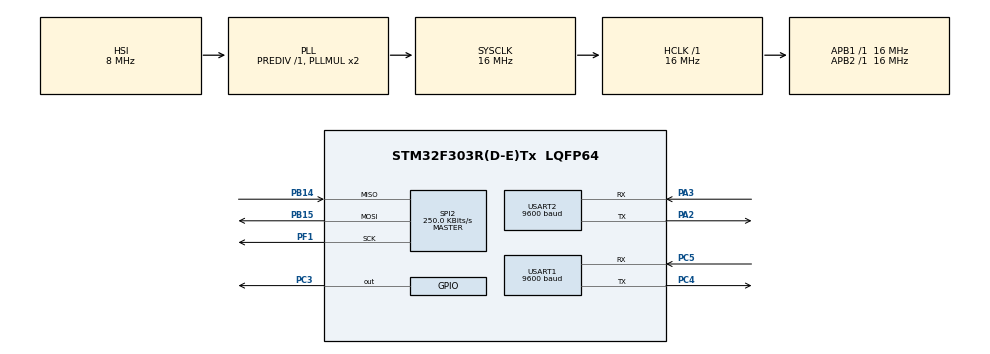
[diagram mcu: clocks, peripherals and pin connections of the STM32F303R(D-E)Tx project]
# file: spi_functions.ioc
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Mcu.Family=STM32F3
Mcu.Name=STM32F303R(D-E)Tx
Mcu.Package=LQFP64
NVIC.PriorityGroup=NVIC_PRIORITYGROUP_4
PA2.Mode=Asynchronous
PA2.Signal=USART2_TX
PA3.Mode=Asynchronous
PA3.Signal=USART2_RX
PB14.Mode=Full_Duplex_Master
PB14.Signal=SPI2_MISO
PB15.Mode=Full_Duplex_Master
PB15.Signal=SPI2_MOSI
PC3.Signal=GPIO_Output
PC4.Mode=Asynchronous
PC4.Signal=USART1_TX
PC5.Mode=Asynchronous
PC5.Signal=USART1_RX
PF1-OSC_OUT.Mode=Full_Duplex_Master
PF1-OSC_OUT.Signal=SPI2_SCK
ProjectManager.HeapSize=0x200
ProjectManager.StackSize=0x400
ProjectManager.TargetToolchain=STM32CubeIDE
RCC.AHBFreq_Value=16000000
RCC.APB1Freq_Value=16000000
RCC.APB1TimFreq_Value=16000000
RCC.APB2Freq_Value=16000000
RCC.APB2TimFreq_Value=16000000
RCC.CortexFreq_Value=16000000
RCC.HCLKFreq_Value=16000000
RCC.HSE_VALUE=8000000
RCC.HSI_VALUE=8000000
RCC.LSE_VALUE=32768
RCC.SYSCLKFreq_VALUE=16000000
RCC.SYSCLKSourceVirtual=RCC_SYSCLKSOURCE_PLLCLK
RCC.USBFreq_Value=16000000
SPI2.BaudRatePrescaler=SPI_BAUDRATEPRESCALER_64
SPI2.CalculateBaudRate=250.0 KBits/s
SPI2.DataSize=SPI_DATASIZE_8BIT
SPI2.Direction=SPI_DIRECTION_2LINES
SPI2.Mode=SPI_MODE_MASTER
SPI2.VirtualType=VM_MASTER
USART1.BaudRate=9600
USART1.Mode=MODE_TX_RX
USART1.OverrunDisableParam=ADVFEATURE_OVERRUN_DISABLE
USART1.VirtualMode-Asynchronous=VM_ASYNC
USART2.BaudRate=9600
USART2.VirtualMode-Asynchronous=VM_ASYNC
board=custom

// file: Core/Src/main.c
/* USER CODE BEGIN Header */
/**
 ******************************************************************************
 * @file           : main.c
 * @brief          : Main program body
 ******************************************************************************
 * @attention
 *
 * Copyright (c) 2022 STMicroelectronics.
 * All rights reserved.
 *
 * This software is licensed under terms that can be found in the LICENSE file
 * in the root directory of this software component.
 * If no LICENSE file comes with this software, it is provided AS-IS.
 *
 ******************************************************************************
 */
/* USER CODE END Header */
#include "main.h"
#include "INC_MAX86178.h"

SPI_HandleTypeDef hspi2;

UART_HandleTypeDef huart1;
UART_HandleTypeDef huart2;

void SystemClock_Config(void);
static void MX_GPIO_Init(void);
static void MX_SPI2_Init(void);
static void MX_USART2_UART_Init(void);
static void MX_USART1_UART_Init(void);

int main(void)
{

  /* MCU Configuration--------------------------------------------------------*/

  /* Reset of all peripherals, Initializes the Flash interface and the Systick. */
  HAL_Init();

  /* Configure the system clock */
  SystemClock_Config();

  /* Initialize all configured peripherals */
  MX_GPIO_Init();
  MX_SPI2_Init();
  MX_USART2_UART_Init();
  MX_USART1_UART_Init();

  /* Infinite loop */
  /* USER CODE BEGIN WHILE */

							////  10011110 10100100 10010100
							//
							////  11110000 00000000 00000000
							//
							//x[2] x[3] x[4]
							//
							// temp=  x[2]>>4
							//
							//base = 0x000000
							//
							//temp2  = 00001111 & x[2]
							//
							//
							//  32 -> x[3]
							//
							//  32 - > x[4]
							//
							//32 - > temp2
							//
							//            temp2    x[3]     x[4]
							//00000000 000000000 00000000 00000000
							//
							//temp3 -> 32 = 000
							//
							//temp2<<16
							//temp3 = temp3 | temp2
							//
							//
							//x[3]<<8
							//temp3 = temp3 | x[3]
							//
							//temp3 = temp3 | x[4]
							//
							//
							//temp3 = -1*temp3 - > value

	///
//	int number=9000;
	unsigned char *x;
//	uint32_t c1=0,c2=0,c3=0,c4=0,c5=0,c6=0,c7=0,c8=0,c9=0;
//	uint32_t sample[number];
//	uint32_t samples_p1_m1[500];
//	uint32_t samples_p2_m1[500];
//	uint32_t samples_p1_m2[500];
//	uint32_t samples_p2_m2[500];
//	uint32_t samples_p1_m3[500];
//	uint32_t samples_p2_m3[500];

//	memset(sample, 0, number*sizeof(sample[0]));

///reading ppg data

	x=ppg_init();

///accumulating samples in a array

//	for (int l =0 ;l<number;l=l+2){
//			sample[l] = *(x+l);
//		}
//
//
/////Segregating samples based on tags
//
//	for(int l=0;l<number;l=l+6){
//
//		temp1 = (uint8_t)sample[l];
//		temp1 = temp1 >> 4;
//
//		switch(temp1){
//
//				case 0x00: // measurement 1 ===> 00
//						{
//							samples_p1_m1[c1] = shifter(sample[l],sample[l+1],sample[l+2]);
//							samples_p2_m1[c1] = shifter(sample[l+3],sample[l+4],sample[l+5]);
//							c1++;
//							break;
//						}
//
//				case 0x01: //measurement 2 ===> 01
//						{
//							samples_p1_m2[c1] = shifter(sample[l],sample[l+1],sample[l+2]);
//							samples_p2_m2[c1] = shifter(sample[l+3],sample[l+4],sample[l+5]);
//							c2++;
//							break;
//						}
//
//
//				case 0x10: //measurement 3 ===>10
//						{
//							samples_p1_m3[c1] = shifter(sample[l],sample[l+1],sample[l+2]);
//							samples_p2_m3[c1] = shifter(sample[l+3],sample[l+4],sample[l+5]);
//							c3++;
//							break;
//						}
//				case 0x11:
//				{
//					c4++;
//					break;
//				}
//				case 0x100:
//				{
//					c5++;
//					break;
//				}
//				case 0x101:
//				{
//					c6++;
//					break;
//				}
//				case 0x110:
//				{
//					c7++;
//					break;
//				}
//				case 0x111:
//				{
//					c8++;
//					break;
//				}
//				default:
//				{
//					c9++;
//					break;
//				}
//
//
//
//			}

//	}

//	HAL_UART_Transmit(&huart1,samples_p2_m1,strlen((char*)samples_p2_m1),HAL_MAX_DELAY);

	/*uint8_t tx1[3]={0xc9,0x00,0xab};
	uint8_t tx2[3]={0xc9,0x80,0xff};
	uint8_t rx[3];
	HAL_GPIO_WritePin(GPIOC,GPIO_PIN_3,GPIO_PIN_SET);

	HAL_GPIO_WritePin(GPIOC,GPIO_PIN_3,GPIO_PIN_RESET);
	HAL_SPI_TransmitReceive(&hspi2, tx2, rx, 3, 1000);
	HAL_GPIO_WritePin(GPIOC,GPIO_PIN_3,GPIO_PIN_SET);

	HAL_GPIO_WritePin(GPIOC,GPIO_PIN_3,GPIO_PIN_RESET);
	HAL_SPI_Transmit(&hspi2, tx1, 3, 1000);
	HAL_GPIO_WritePin(GPIOC,GPIO_PIN_3,GPIO_PIN_SET);

	HAL_GPIO_WritePin(GPIOC,GPIO_PIN_3,GPIO_PIN_RESET);
	HAL_SPI_TransmitReceive(&hspi2, tx2, rx, 3, 1000);
	HAL_GPIO_WritePin(GPIOC,GPIO_PIN_3,GPIO_PIN_SET);

	 */

    /* USER CODE END WHILE */

}

void SystemClock_Config(void)
{
  RCC_OscInitTypeDef RCC_OscInitStruct = {0};
  RCC_ClkInitTypeDef RCC_ClkInitStruct = {0};
  RCC_PeriphCLKInitTypeDef PeriphClkInit = {0};

  /** Initializes the RCC Oscillators according to the specified parameters
  * in the RCC_OscInitTypeDef structure.
  */
  RCC_OscInitStruct.OscillatorType = RCC_OSCILLATORTYPE_HSI;
  RCC_OscInitStruct.HSIState = RCC_HSI_ON;
  RCC_OscInitStruct.HSICalibrationValue = RCC_HSICALIBRATION_DEFAULT;
  RCC_OscInitStruct.PLL.PLLState = RCC_PLL_ON;
  RCC_OscInitStruct.PLL.PLLSource = RCC_PLLSOURCE_HSI;
  RCC_OscInitStruct.PLL.PLLMUL = RCC_PLL_MUL2;
  RCC_OscInitStruct.PLL.PREDIV = RCC_PREDIV_DIV1;
  if (HAL_RCC_OscConfig(&RCC_OscInitStruct) != HAL_OK)
  {
    Error_Handler();
  }

  /** Initializes the CPU, AHB and APB buses clocks
  */
  RCC_ClkInitStruct.ClockType = RCC_CLOCKTYPE_HCLK|RCC_CLOCKTYPE_SYSCLK
                              |RCC_CLOCKTYPE_PCLK1|RCC_CLOCKTYPE_PCLK2;
  RCC_ClkInitStruct.SYSCLKSource = RCC_SYSCLKSOURCE_PLLCLK;
  RCC_ClkInitStruct.AHBCLKDivider = RCC_SYSCLK_DIV1;
  RCC_ClkInitStruct.APB1CLKDivider = RCC_HCLK_DIV1;
  RCC_ClkInitStruct.APB2CLKDivider = RCC_HCLK_DIV1;

  if (HAL_RCC_ClockConfig(&RCC_ClkInitStruct, FLASH_LATENCY_0) != HAL_OK)
  {
    Error_Handler();
  }
  PeriphClkInit.PeriphClockSelection = RCC_PERIPHCLK_USART1|RCC_PERIPHCLK_USART2;
  PeriphClkInit.Usart1ClockSelection = RCC_USART1CLKSOURCE_PCLK2;
  PeriphClkInit.Usart2ClockSelection = RCC_USART2CLKSOURCE_PCLK1;
  if (HAL_RCCEx_PeriphCLKConfig(&PeriphClkInit) != HAL_OK)
  {
    Error_Handler();
  }
}

static void MX_SPI2_Init(void)
{

  /* SPI2 parameter configuration*/
  hspi2.Instance = SPI2;
  hspi2.Init.Mode = SPI_MODE_MASTER;
  hspi2.Init.Direction = SPI_DIRECTION_2LINES;
  hspi2.Init.DataSize = SPI_DATASIZE_8BIT;
  hspi2.Init.CLKPolarity = SPI_POLARITY_LOW;
  hspi2.Init.CLKPhase = SPI_PHASE_1EDGE;
  hspi2.Init.NSS = SPI_NSS_SOFT;
  hspi2.Init.BaudRatePrescaler = SPI_BAUDRATEPRESCALER_64;
  hspi2.Init.FirstBit = SPI_FIRSTBIT_MSB;
  hspi2.Init.TIMode = SPI_TIMODE_DISABLE;
  hspi2.Init.CRCCalculation = SPI_CRCCALCULATION_DISABLE;
  hspi2.Init.CRCPolynomial = 7;
  hspi2.Init.CRCLength = SPI_CRC_LENGTH_DATASIZE;
  hspi2.Init.NSSPMode = SPI_NSS_PULSE_ENABLE;
  if (HAL_SPI_Init(&hspi2) != HAL_OK)
  {
    Error_Handler();
  }

}

static void MX_USART1_UART_Init(void)
{

  huart1.Instance = USART1;
  huart1.Init.BaudRate = 9600;
  huart1.Init.WordLength = UART_WORDLENGTH_8B;
  huart1.Init.StopBits = UART_STOPBITS_1;
  huart1.Init.Parity = UART_PARITY_NONE;
  huart1.Init.Mode = UART_MODE_TX_RX;
  huart1.Init.HwFlowCtl = UART_HWCONTROL_NONE;
  huart1.Init.OverSampling = UART_OVERSAMPLING_16;
  huart1.Init.OneBitSampling = UART_ONE_BIT_SAMPLE_DISABLE;
  huart1.AdvancedInit.AdvFeatureInit = UART_ADVFEATURE_RXOVERRUNDISABLE_INIT;
  huart1.AdvancedInit.OverrunDisable = UART_ADVFEATURE_OVERRUN_DISABLE;
  if (HAL_UART_Init(&huart1) != HAL_OK)
  {
    Error_Handler();
  }

}

static void MX_USART2_UART_Init(void)
{

  huart2.Instance = USART2;
  huart2.Init.BaudRate = 9600;
  huart2.Init.WordLength = UART_WORDLENGTH_8B;
  huart2.Init.StopBits = UART_STOPBITS_1;
  huart2.Init.Parity = UART_PARITY_NONE;
  huart2.Init.Mode = UART_MODE_TX_RX;
  huart2.Init.HwFlowCtl = UART_HWCONTROL_NONE;
  huart2.Init.OverSampling = UART_OVERSAMPLING_16;
  huart2.Init.OneBitSampling = UART_ONE_BIT_SAMPLE_DISABLE;
  huart2.AdvancedInit.AdvFeatureInit = UART_ADVFEATURE_NO_INIT;
  if (HAL_UART_Init(&huart2) != HAL_OK)
  {
    Error_Handler();
  }

}

static void MX_GPIO_Init(void)
{
  GPIO_InitTypeDef GPIO_InitStruct = {0};

  /* GPIO Ports Clock Enable */
  __HAL_RCC_GPIOF_CLK_ENABLE();
  __HAL_RCC_GPIOC_CLK_ENABLE();
  __HAL_RCC_GPIOA_CLK_ENABLE();
  __HAL_RCC_GPIOB_CLK_ENABLE();

  /*Configure GPIO pin Output Level */
  HAL_GPIO_WritePin(GPIOC, GPIO_PIN_3, GPIO_PIN_RESET);

  /*Configure GPIO pin : PC3 */
  GPIO_InitStruct.Pin = GPIO_PIN_3;
  GPIO_InitStruct.Mode = GPIO_MODE_OUTPUT_PP;
  GPIO_InitStruct.Pull = GPIO_NOPULL;
  GPIO_InitStruct.Speed = GPIO_SPEED_FREQ_LOW;
  HAL_GPIO_Init(GPIOC, &GPIO_InitStruct);

}

void Error_Handler(void)
{
	__disable_irq();
	while (1)
	{
	}
}
